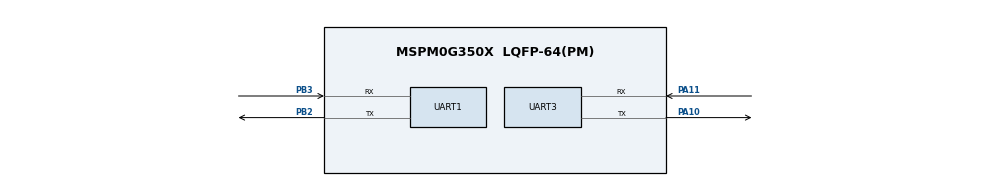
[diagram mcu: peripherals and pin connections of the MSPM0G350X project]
/**
 * @cliArgs --device "MSPM0G350X" --part "Default" --package "LQFP-64(PM)" --product "mspm0_sdk@2.10.00.04"
 * @versions {"tool":"1.26.2+4477"}
 */

/**
 * Import the modules used in this configuration.
 */
const GPIO          = scripting.addModule("/ti/driverlib/GPIO", {}, false);
const GPIO1         = GPIO.addInstance();
const SYSCTL        = scripting.addModule("/ti/driverlib/SYSCTL");
const UART          = scripting.addModule("/ti/driverlib/UART", {}, false);
const UART1         = UART.addInstance();
const UART2         = UART.addInstance();
const UART3         = UART.addInstance();
const ProjectConfig = scripting.addModule("/ti/project_config/ProjectConfig");

/**
 * Write custom configuration values to the imported modules.
 */
GPIO1.$name                          = "LED1";
GPIO1.associatedPins[0].assignedPort = "PORTA";
GPIO1.associatedPins[0].assignedPin  = "14";
GPIO1.associatedPins[0].$name        = "PIN_14";

const Board = scripting.addModule("/ti/driverlib/Board", {}, false);

SYSCTL.clockTreeEn = true;

UART1.enableFIFO                       = true;
UART1.enableDMARX                      = false;
UART1.enableDMATX                      = false;
UART1.$name                            = "UART_3";
UART1.rxFifoThreshold                  = "DL_UART_RX_FIFO_LEVEL_3_4_FULL";
UART1.rxTimeoutValue                   = 15;
UART1.targetBaudRate                   = 115200;
UART1.flowControl                      = "NONE";
UART1.txPinConfig.$name                = "ti_driverlib_gpio_GPIOPinGeneric0";
UART1.txPinConfig.direction            = scripting.forceWrite("OUTPUT");
UART1.txPinConfig.hideOutputInversion  = scripting.forceWrite(false);
UART1.txPinConfig.onlyInternalResistor = scripting.forceWrite(false);
UART1.txPinConfig.passedPeripheralType = scripting.forceWrite("Digital");
UART1.rxPinConfig.$name                = "ti_driverlib_gpio_GPIOPinGeneric1";
UART1.rxPinConfig.hideOutputInversion  = scripting.forceWrite(false);
UART1.rxPinConfig.onlyInternalResistor = scripting.forceWrite(false);
UART1.rxPinConfig.passedPeripheralType = scripting.forceWrite("Digital");
UART1.peripheral.rxPin.$assign         = "PB3";
UART1.peripheral.txPin.$assign         = "PB2";

UART2.$name              = "UART_1";
UART2.enableFIFO         = true;
UART2.enableDMARX        = false;
UART2.enableDMATX        = false;
UART2.rxFifoThreshold    = "DL_UART_RX_FIFO_LEVEL_3_4_FULL";
UART2.rxTimeoutValue     = 15;
UART2.targetBaudRate     = 115200;
UART2.flowControl        = "NONE";
UART2.txPinConfig.$name  = "ti_driverlib_gpio_GPIOPinGeneric2";
UART2.rxPinConfig.$name  = "ti_driverlib_gpio_GPIOPinGeneric3";
UART2.peripheral.$assign = "UART1";

UART3.$name                            = "UART_0";
UART3.enableFIFO                       = true;
UART3.enableDMARX                      = false;
UART3.enableDMATX                      = false;
UART3.rxFifoThreshold                  = "DL_UART_RX_FIFO_LEVEL_3_4_FULL";
UART3.rxTimeoutValue                   = 15;
UART3.targetBaudRate                   = 115200;
UART3.flowControl                      = "NONE";
UART3.txPinConfig.$name                = "ti_driverlib_gpio_GPIOPinGeneric4";
UART3.txPinConfig.direction            = scripting.forceWrite("OUTPUT");
UART3.txPinConfig.hideOutputInversion  = scripting.forceWrite(false);
UART3.txPinConfig.onlyInternalResistor = scripting.forceWrite(false);
UART3.txPinConfig.passedPeripheralType = scripting.forceWrite("Digital");
UART3.rxPinConfig.$name                = "ti_driverlib_gpio_GPIOPinGeneric5";
UART3.rxPinConfig.hideOutputInversion  = scripting.forceWrite(false);
UART3.rxPinConfig.onlyInternalResistor = scripting.forceWrite(false);
UART3.rxPinConfig.passedPeripheralType = scripting.forceWrite("Digital");
UART3.peripheral.rxPin.$assign         = "PA11";
UART3.peripheral.txPin.$assign         = "PA10";

ProjectConfig.genDisable = true;

/**
 * Pinmux solution for unlocked pins/peripherals. This ensures that minor changes to the automatic solver in a future
 * version of the tool will not impact the pinmux you originally saw.  These lines can be completely deleted in order to
 * re-solve from scratch.
 */
GPIO1.associatedPins[0].pin.$suggestSolution = "PA14";
Board.peripheral.$suggestSolution            = "DEBUGSS";
Board.peripheral.swclkPin.$suggestSolution   = "PA20";
Board.peripheral.swdioPin.$suggestSolution   = "PA19";
UART1.peripheral.$suggestSolution            = "UART3";
UART2.peripheral.rxPin.$suggestSolution      = "PA18";
UART2.peripheral.txPin.$suggestSolution      = "PA17";
UART3.peripheral.$suggestSolution            = "UART0";
